VERSION "1.0"

NS_ :

BS_:

BU_: ENGINE_ECU BODY_ECU DASH

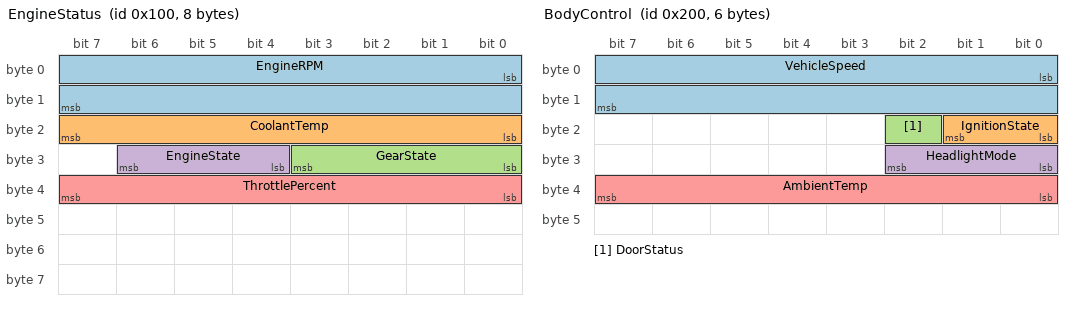
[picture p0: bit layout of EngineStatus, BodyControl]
BO_ 256 EngineStatus: 8 ENGINE_ECU
 SG_ EngineRPM : 0|16@1+ (0.25,0) [0|16383.75] "rpm" DASH
 SG_ CoolantTemp : 16|8@1+ (1,-40) [-40|215] "degC" DASH
 SG_ GearState : 24|4@1+ (1,0) [0|7] "" DASH
 SG_ EngineState : 28|3@1+ (1,0) [0|4] "" DASH
 SG_ ThrottlePercent : 32|8@1+ (0.5,0) [0|100] "%" DASH

BO_ 512 BodyControl: 6 BODY_ECU
 SG_ VehicleSpeed : 0|16@1+ (0.01,0) [0|655.35] "km/h" DASH
 SG_ IgnitionState : 16|2@1+ (1,0) [0|3] "" DASH
 SG_ DoorStatus : 18|1@1+ (1,0) [0|1] "" DASH
 SG_ HeadlightMode : 24|3@1+ (1,0) [0|5] "" DASH
 SG_ AmbientTemp : 32|8@1- (0.5,0) [-40|87.5] "degC" DASH

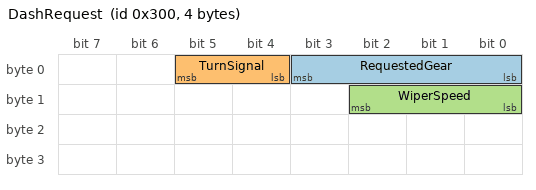
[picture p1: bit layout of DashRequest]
BO_ 768 DashRequest: 4 DASH
 SG_ RequestedGear : 0|4@1+ (1,0) [0|7] "" ENGINE_ECU
 SG_ TurnSignal : 4|2@1+ (1,0) [0|3] "" BODY_ECU
 SG_ WiperSpeed : 8|3@1+ (1,0) [0|4] "" BODY_ECU

CM_ BO_ 256 "Live engine operating status broadcast by the engine ECU.";
CM_ SG_ 256 GearState "Currently engaged transmission gear.";
CM_ SG_ 256 EngineState "High level engine run state.";
CM_ SG_ 512 IgnitionState "Ignition key / start button position.";
CM_ SG_ 768 RequestedGear "Gear the driver has requested via the shifter.";

VAL_ 256 GearState 0 "Park" 1 "Reverse" 2 "Neutral" 3 "First" 4 "Second" 5 "Third" 6 "Fourth" 7 "Fifth" ;
VAL_ 256 EngineState 0 "Off" 1 "Cranking" 2 "Running" 3 "Stalled" 4 "Fault" ;
VAL_ 512 IgnitionState 0 "Off" 1 "Accessory" 2 "On" 3 "Start" ;
VAL_ 512 DoorStatus 0 "Closed" 1 "Open" ;
VAL_ 512 HeadlightMode 0 "Off" 1 "Parking" 2 "LowBeam" 3 "HighBeam" 4 "Automatic" 5 "Fog" ;
VAL_ 768 RequestedGear 0 "Park" 1 "Reverse" 2 "Neutral" 3 "Drive" 4 "Sport" 5 "Low" 6 "Manual" 7 "Invalid" ;
VAL_ 768 TurnSignal 0 "None" 1 "Left" 2 "Right" 3 "Hazard" ;
VAL_ 768 WiperSpeed 0 "Off" 1 "Intermittent" 2 "Low" 3 "High" 4 "Mist" ;
